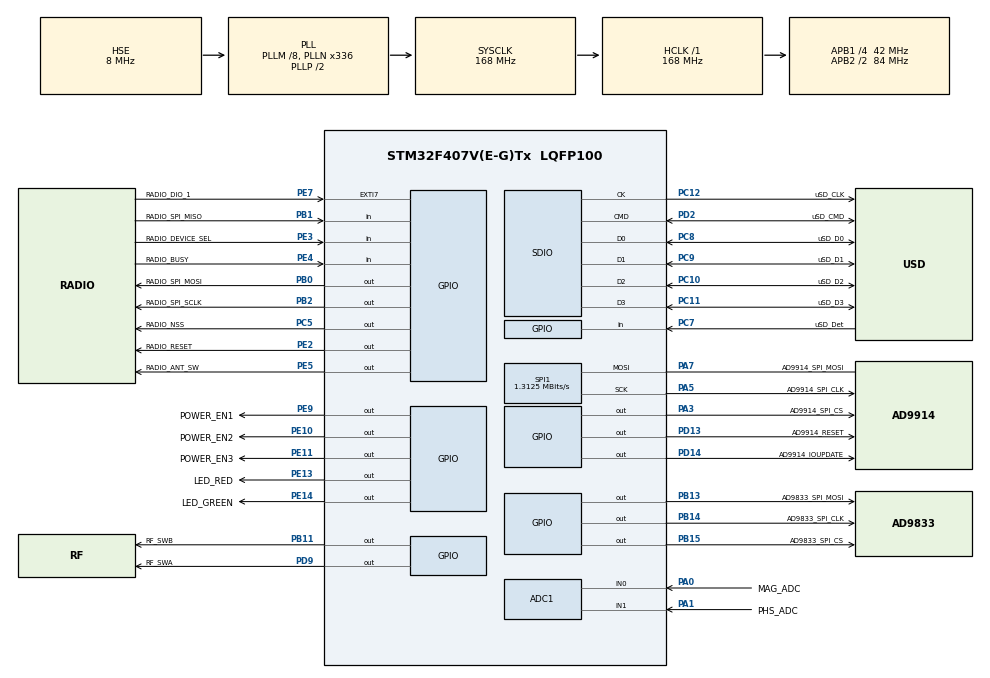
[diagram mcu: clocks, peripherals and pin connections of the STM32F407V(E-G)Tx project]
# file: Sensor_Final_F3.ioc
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ADC1.Channel-0\#ChannelRegularConversion=ADC_CHANNEL_0
ADC1.Channel-1\#ChannelRegularConversion=ADC_CHANNEL_1
ADC1.ContinuousConvMode=ENABLE
ADC1.NbrOfConversion=2
ADC1.NbrOfConversionFlag=1
ADC1.Rank-0\#ChannelRegularConversion=1
ADC1.Rank-1\#ChannelRegularConversion=2
ADC1.SamplingTime-0\#ChannelRegularConversion=ADC_SAMPLETIME_3CYCLES
ADC1.SamplingTime-1\#ChannelRegularConversion=ADC_SAMPLETIME_3CYCLES
ADC1.ScanConvMode=ENABLE
ADC1.master=1
Dma.ADC1.0.Direction=DMA_PERIPH_TO_MEMORY
Dma.ADC1.0.FIFOMode=DMA_FIFOMODE_DISABLE
Dma.ADC1.0.Instance=DMA2_Stream0
Dma.ADC1.0.MemDataAlignment=DMA_MDATAALIGN_HALFWORD
Dma.ADC1.0.MemInc=DMA_MINC_ENABLE
Dma.ADC1.0.Mode=DMA_NORMAL
Dma.ADC1.0.PeriphDataAlignment=DMA_PDATAALIGN_HALFWORD
Dma.ADC1.0.PeriphInc=DMA_PINC_DISABLE
Dma.ADC1.0.Priority=DMA_PRIORITY_LOW
Dma.Request0=ADC1
FATFS.BSP.number=1
FATFS._MAX_LFN=30
FATFS._MAX_SS=4096
FATFS._USE_LFN=1
FATFS0.BSP.STBoard=false
FATFS0.BSP.api=Unknown
FATFS0.BSP.instance=PC7
FATFS0.BSP.ip=GPIO
FATFS0.BSP.mode=Input
FATFS0.BSP.name=Detect_SDIO
FATFS0.BSP.solution=PC7
Mcu.Family=STM32F4
Mcu.Name=STM32F407V(E-G)Tx
Mcu.Package=LQFP100
NVIC.DMA2_Stream0_IRQn=true\:0\:0\:false\:false\:true\:false\:true\:true
NVIC.EXTI9_5_IRQn=true\:0\:0\:false\:false\:true\:true\:true\:true
NVIC.PriorityGroup=NVIC_PRIORITYGROUP_0
NVIC.RTC_Alarm_IRQn=true\:0\:0\:false\:false\:true\:true\:true\:true
NVIC.RTC_WKUP_IRQn=true\:0\:0\:false\:false\:true\:true\:true\:true
PA0-WKUP.GPIO_Label=MAG_ADC
PA0-WKUP.Signal=ADCx_IN0
PA1.GPIO_Label=PHS_ADC
PA1.Signal=ADCx_IN1
PA13.GPIO_Label=SWDIO
PA13.Mode=Trace_Asynchronous_SW
PA13.Signal=SYS_JTMS-SWDIO
PA14.GPIO_Label=SWCLK
PA14.Mode=Trace_Asynchronous_SW
PA14.Signal=SYS_JTCK-SWCLK
PA3.GPIO_Label=AD9914_SPI_CS
PA3.GPIO_ModeDefaultOutputPP=GPIO_MODE_OUTPUT_PP
PA3.GPIO_PuPd=GPIO_PULLDOWN
PA3.Signal=GPIO_Output
PA5.GPIO_Label=AD9914_SPI_CLK
PA5.GPIO_PuPd=GPIO_PULLUP
PA5.Mode=Simplex_Bidirectional_Master
PA5.Signal=SPI1_SCK
PA7.GPIO_Label=AD9914_SPI_MOSI
PA7.GPIO_PuPd=GPIO_PULLUP
PA7.Mode=Simplex_Bidirectional_Master
PA7.Signal=SPI1_MOSI
PB0.GPIO_Label=RADIO_SPI_MOSI
PB0.GPIO_PuPd=GPIO_PULLUP
PB0.GPIO_Speed=GPIO_SPEED_FREQ_HIGH
PB0.Signal=GPIO_Output
PB1.GPIO_Label=RADIO_SPI_MISO
PB1.GPIO_PuPd=GPIO_PULLUP
PB1.Signal=GPIO_Input
PB11.GPIO_Label=RF_SWB
PB11.GPIO_PuPd=GPIO_PULLDOWN
PB11.Signal=GPIO_Output
PB13.GPIO_Label=AD9833_SPI_MOSI
PB13.GPIO_ModeDefaultOutputPP=GPIO_MODE_OUTPUT_PP
PB13.GPIO_PuPd=GPIO_PULLUP
PB13.GPIO_Speed=GPIO_SPEED_FREQ_HIGH
PB13.Signal=GPIO_Output
PB14.GPIO_Label=AD9833_SPI_CLK
PB14.GPIO_ModeDefaultOutputPP=GPIO_MODE_OUTPUT_PP
PB14.GPIO_PuPd=GPIO_PULLUP
PB14.GPIO_Speed=GPIO_SPEED_FREQ_HIGH
PB14.Signal=GPIO_Output
PB15.GPIO_Label=AD9833_SPI_CS
PB15.GPIO_ModeDefaultOutputPP=GPIO_MODE_OUTPUT_PP
PB15.GPIO_PuPd=GPIO_PULLUP
PB15.GPIO_Speed=GPIO_SPEED_FREQ_HIGH
PB15.Signal=GPIO_Output
PB2.GPIO_Label=RADIO_SPI_SCLK
PB2.GPIO_PuPd=GPIO_PULLUP
PB2.GPIO_Speed=GPIO_SPEED_FREQ_HIGH
PB2.Signal=GPIO_Output
PB3.GPIO_Label=SWO
PB3.Mode=Trace_Asynchronous_SW
PB3.Signal=SYS_JTDO-SWO
PC10.GPIO_Label=uSD_D2
PC10.Mode=SD_4_bits_Wide_bus
PC10.Signal=SDIO_D2
PC11.GPIO_Label=uSD_D3
PC11.Mode=SD_4_bits_Wide_bus
PC11.Signal=SDIO_D3
PC12.GPIO_Label=uSD_CLK
PC12.Mode=SD_4_bits_Wide_bus
PC12.Signal=SDIO_CK
PC14-OSC32_IN.Mode=LSE-External-Clock-Source
PC14-OSC32_IN.Signal=RCC_OSC32_IN
PC15-OSC32_OUT.Mode=LSE-External-Clock-Source
PC15-OSC32_OUT.Signal=RCC_OSC32_OUT
PC5.GPIO_Label=RADIO_NSS
PC5.GPIO_PuPd=GPIO_PULLDOWN
PC5.Signal=GPIO_Output
PC7.GPIO_Label=uSD_Det
PC7.GPIO_PuPd=GPIO_PULLDOWN
PC7.Signal=GPIO_Input
PC8.GPIO_Label=uSD_D0
PC8.Mode=SD_4_bits_Wide_bus
PC8.Signal=SDIO_D0
PC9.GPIO_Label=uSD_D1
PC9.Mode=SD_4_bits_Wide_bus
PC9.Signal=SDIO_D1
PD13.GPIO_Label=AD9914_RESET
PD13.GPIO_PuPd=GPIO_PULLDOWN
PD13.Signal=GPIO_Output
PD14.GPIO_Label=AD9914_IOUPDATE
PD14.GPIO_PuPd=GPIO_PULLDOWN
PD14.Signal=GPIO_Output
PD2.GPIO_Label=uSD_CMD
PD2.Mode=SD_4_bits_Wide_bus
PD2.Signal=SDIO_CMD
PD9.GPIO_Label=RF_SWA
PD9.GPIO_PuPd=GPIO_PULLDOWN
PD9.Signal=GPIO_Output
PE10.GPIO_Label=POWER_EN2
PE10.GPIO_PuPd=GPIO_PULLDOWN
PE10.GPIO_Speed=GPIO_SPEED_FREQ_HIGH
PE10.Signal=GPIO_Output
PE11.GPIO_Label=POWER_EN3
PE11.GPIO_PuPd=GPIO_PULLDOWN
PE11.GPIO_Speed=GPIO_SPEED_FREQ_HIGH
PE11.Signal=GPIO_Output
PE13.GPIO_Label=LED_RED
PE13.GPIO_PuPd=GPIO_PULLDOWN
PE13.Signal=GPIO_Output
PE14.GPIO_Label=LED_GREEN
PE14.GPIO_PuPd=GPIO_PULLDOWN
PE14.Signal=GPIO_Output
PE2.GPIO_Label=RADIO_RESET
PE2.GPIO_PuPd=GPIO_PULLUP
PE2.Signal=GPIO_Output
PE3.GPIO_Label=RADIO_DEVICE_SEL
PE3.GPIO_PuPd=GPIO_PULLDOWN
PE3.Signal=GPIO_Input
PE4.GPIO_Label=RADIO_BUSY
PE4.GPIO_PuPd=GPIO_PULLDOWN
PE4.Signal=GPIO_Input
PE5.GPIO_Label=RADIO_ANT_SW
PE5.GPIO_PuPd=GPIO_PULLDOWN
PE5.PinState=GPIO_PIN_RESET
PE5.Signal=GPIO_Output
PE7.GPIO_Label=RADIO_DIO_1
PE7.GPIO_PuPd=GPIO_PULLDOWN
PE7.Signal=GPXTI7
PE9.GPIO_Label=POWER_EN1
PE9.GPIO_ModeDefaultOutputPP=GPIO_MODE_OUTPUT_PP
PE9.GPIO_PuPd=GPIO_PULLDOWN
PE9.GPIO_Speed=GPIO_SPEED_FREQ_HIGH
PE9.Signal=GPIO_Output
PH0-OSC_IN.Mode=HSE-External-Oscillator
PH0-OSC_IN.Signal=RCC_OSC_IN
PH1-OSC_OUT.Mode=HSE-External-Oscillator
PH1-OSC_OUT.Signal=RCC_OSC_OUT
ProjectManager.HeapSize=0x200
ProjectManager.StackSize=0x400
ProjectManager.TargetToolchain=STM32CubeIDE
RCC.48MHZClocksFreq_Value=48000000
RCC.AHBFreq_Value=168000000
RCC.APB1CLKDivider=RCC_HCLK_DIV4
RCC.APB1Freq_Value=42000000
RCC.APB1TimFreq_Value=84000000
RCC.APB2CLKDivider=RCC_HCLK_DIV2
RCC.APB2Freq_Value=84000000
RCC.APB2TimFreq_Value=168000000
RCC.CortexFreq_Value=168000000
RCC.HCLKFreq_Value=168000000
RCC.HSE_VALUE=8000000
RCC.HSI_VALUE=16000000
RCC.LSE_VALUE=32768
RCC.PLLM=8
RCC.PLLN=336
RCC.PLLQ=7
RCC.PLLSourceVirtual=RCC_PLLSOURCE_HSE
RCC.RCC_RTC_Clock_SourceVirtual=RCC_RTCCLKSOURCE_LSE
RCC.SYSCLKFreq_VALUE=168000000
RCC.SYSCLKSource=RCC_SYSCLKSOURCE_PLLCLK
RCC.VCOOutputFreq_Value=336000000
RTC.Alarm=RTC_ALARM_A
RTC.AlarmMaskDateWeekDay=RTC_ALARMMASK_DATEWEEKDAY
RTC.AlarmMaskDateWeekDay_B=RTC_ALARMMASK_DATEWEEKDAY
RTC.Alarm_B=RTC_ALARM_B
RTC.DayLightSaving=RTC_DAYLIGHTSAVING_SUB1H
RTC.Format=RTC_FORMAT_BIN
RTC.Hours=17
RTC.Hours_A=11
RTC.Minutes=33
RTC.Minutes_A=59
RTC.Month=RTC_MONTH_APRIL
RTC.Seconds=0
RTC.Seconds_A=30
RTC.WakeUpClock=RTC_WAKEUPCLOCK_CK_SPRE_16BITS
RTC.WakeUpCounter=60
RTC.Year=24
SDIO.ClockDiv=4
SH.ADCx_IN0.0=ADC1_IN0,IN0
SH.ADCx_IN1.0=ADC1_IN1,IN1
SPI1.BaudRatePrescaler=SPI_BAUDRATEPRESCALER_64
SPI1.CalculateBaudRate=1.3125 MBits/s
SPI1.Direction=SPI_DIRECTION_1LINE
SPI1.Mode=SPI_MODE_MASTER
SPI1.VirtualType=VM_MASTER
VP_FATFS_VS_SDIO.Mode=SDIO
VP_RTC_VS_RTC_Activate.Mode=RTC_Enabled
VP_RTC_VS_RTC_Alarm_A_Intern.Mode=Alarm A
VP_RTC_VS_RTC_Alarm_B_Intern.Mode=Alarm B
VP_RTC_VS_RTC_Calendar.Mode=RTC_Calendar
VP_RTC_VS_RTC_WakeUp_intern.Mode=WakeUp
board=custom

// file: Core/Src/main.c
/* USER CODE BEGIN Header */
/**
  ******************************************************************************
  * @file           : main.c
  * @brief          : Main program body
  ******************************************************************************
  * @attention
  *
  * Copyright (c) 2023 STMicroelectronics.
  * All rights reserved.
  *
  * This software is licensed under terms that can be found in the LICENSE file
  * in the root directory of this software component.
  * If no LICENSE file comes with this software, it is provided AS-IS.
  *
  ******************************************************************************
  */
/* USER CODE END Header */
#include "main.h"
#include "adc.h"
#include "dma.h"
#include "fatfs.h"
#include "rtc.h"
#include "sdio.h"
#include "spi.h"
#include "gpio.h"

/* USER CODE BEGIN Includes */
#include "Sensor_Drivers.h"
/* USER CODE END Includes */

void SystemClock_Config(void);

int main(void)
{

  /* MCU Configuration--------------------------------------------------------*/

  /* Reset of all peripherals, Initializes the Flash interface and the Systick. */
  HAL_Init();

  /* USER CODE BEGIN Init */
  // SystemClock_Config_User();
  /* USER CODE END Init */

  /* Configure the system clock */
  SystemClock_Config();

  /* Initialize all configured peripherals */
  MX_GPIO_Init();
  MX_DMA_Init();
  MX_SDIO_SD_Init();
  MX_FATFS_Init();
  MX_SPI1_Init();
  MX_ADC1_Init();
  MX_RTC_Init();
  /* USER CODE BEGIN 2 */

  RTC_Time_Setup();
  Alarms_Setup();
  Sensor_MX_Process();
  /*
  HAL_GPIO_WritePin(GPIOE, LED_RED_Pin, GPIO_PIN_SET);
  HAL_Delay(5000);
  HAL_GPIO_WritePin(GPIOE, LED_GREEN_Pin, GPIO_PIN_SET);
  HAL_Delay(5000);
  HAL_GPIO_WritePin(GPIOE, LED_RED_Pin|LED_GREEN_Pin, GPIO_PIN_RESET);
  HAL_Delay(5000);
  HAL_GPIO_WritePin(GPIOE, LED_RED_Pin|LED_GREEN_Pin, GPIO_PIN_SET);
  */
  /* USER CODE END 2 */

  /* Infinite loop */
  while (1)
  {

  }
}

void SystemClock_Config(void)
{
  RCC_OscInitTypeDef RCC_OscInitStruct = {0};
  RCC_ClkInitTypeDef RCC_ClkInitStruct = {0};

  /** Configure the main internal regulator output voltage
  */
  __HAL_RCC_PWR_CLK_ENABLE();
  __HAL_PWR_VOLTAGESCALING_CONFIG(PWR_REGULATOR_VOLTAGE_SCALE1);

  /** Initializes the RCC Oscillators according to the specified parameters
  * in the RCC_OscInitTypeDef structure.
  */
  RCC_OscInitStruct.OscillatorType = RCC_OSCILLATORTYPE_HSE|RCC_OSCILLATORTYPE_LSE;
  RCC_OscInitStruct.HSEState = RCC_HSE_ON;
  RCC_OscInitStruct.LSEState = RCC_LSE_BYPASS;
  RCC_OscInitStruct.PLL.PLLState = RCC_PLL_ON;
  RCC_OscInitStruct.PLL.PLLSource = RCC_PLLSOURCE_HSE;
  RCC_OscInitStruct.PLL.PLLM = 8;
  RCC_OscInitStruct.PLL.PLLN = 336;
  RCC_OscInitStruct.PLL.PLLP = RCC_PLLP_DIV2;
  RCC_OscInitStruct.PLL.PLLQ = 7;
  if (HAL_RCC_OscConfig(&RCC_OscInitStruct) != HAL_OK)
  {
    Error_Handler();
  }

  /** Initializes the CPU, AHB and APB buses clocks
  */
  RCC_ClkInitStruct.ClockType = RCC_CLOCKTYPE_HCLK|RCC_CLOCKTYPE_SYSCLK
                              |RCC_CLOCKTYPE_PCLK1|RCC_CLOCKTYPE_PCLK2;
  RCC_ClkInitStruct.SYSCLKSource = RCC_SYSCLKSOURCE_PLLCLK;
  RCC_ClkInitStruct.AHBCLKDivider = RCC_SYSCLK_DIV1;
  RCC_ClkInitStruct.APB1CLKDivider = RCC_HCLK_DIV4;
  RCC_ClkInitStruct.APB2CLKDivider = RCC_HCLK_DIV2;

  if (HAL_RCC_ClockConfig(&RCC_ClkInitStruct, FLASH_LATENCY_5) != HAL_OK)
  {
    Error_Handler();
  }
}

void Error_Handler(void)
{
  __disable_irq();
  while (1)
  {
  }
}
